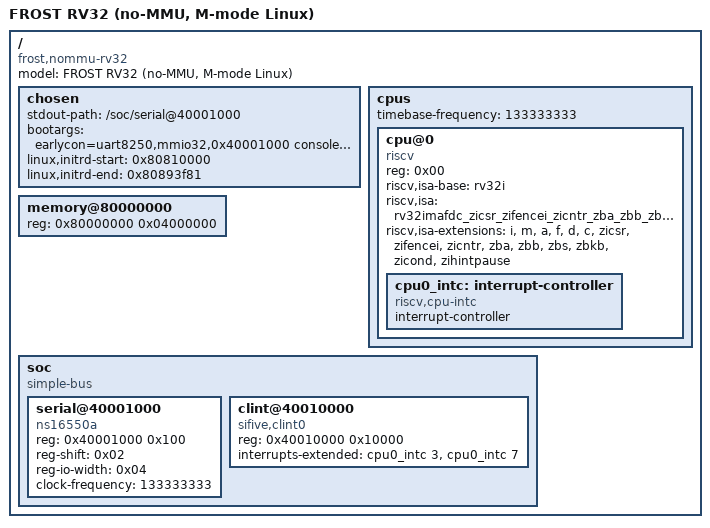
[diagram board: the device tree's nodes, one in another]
/dts-v1/;

/ {
	#address-cells = <0x01>;
	#size-cells = <0x01>;
	compatible = "frost,nommu-rv32", "frost";
	model = "FROST RV32 (no-MMU, M-mode Linux)";

	chosen {
		stdout-path = "/soc/serial@40001000";
		bootargs = "earlycon=uart8250,mmio32,0x40001000 console=ttyS0 rdinit=/sbin/init";
		linux,initrd-start = <0x80810000>;
		linux,initrd-end = <0x80893f81>;
	};

	cpus {
		#address-cells = <0x01>;
		#size-cells = <0x00>;
		timebase-frequency = <133333333>;

		cpu@0 {
			device_type = "cpu";
			reg = <0x00>;
			status = "okay";
			compatible = "riscv";
			riscv,isa-base = "rv32i";
			riscv,isa = "rv32imafdc_zicsr_zifencei_zicntr_zba_zbb_zbs_zbkb_zicond_zihintpause";
			riscv,isa-extensions = "i", "m", "a", "f", "d", "c",
				"zicsr", "zifencei", "zicntr",
				"zba", "zbb", "zbs", "zbkb",
				"zicond", "zihintpause";

			cpu0_intc: interrupt-controller {
				#interrupt-cells = <0x01>;
				interrupt-controller;
				compatible = "riscv,cpu-intc";
				phandle = <0x01>;
			};
		};
	};

	memory@80000000 {
		device_type = "memory";
		reg = <0x80000000 0x04000000>;
	};

	soc {
		#address-cells = <0x01>;
		#size-cells = <0x01>;
		compatible = "simple-bus";
		ranges;

		serial@40001000 {
			compatible = "ns16550a";
			reg = <0x40001000 0x100>;
			reg-shift = <0x02>;
			reg-io-width = <0x04>;
			clock-frequency = <133333333>;
		};

		clint@40010000 {
			compatible = "sifive,clint0", "riscv,clint0";
			reg = <0x40010000 0x10000>;
			interrupts-extended = <&cpu0_intc 3 &cpu0_intc 7>;
		};
	};
};
